# STM32F302x register map
File version: 1.1
Registers are 32-bit, read-write, reset 0x0 unless marked. A register's access mark holds for its fields unless they carry their own. Offsets are from the block's base; [hi:lo] are bit positions; {n}, {i} and the like mark numbered series.

## DBGMCU — Debug support
Base 0xE0042000
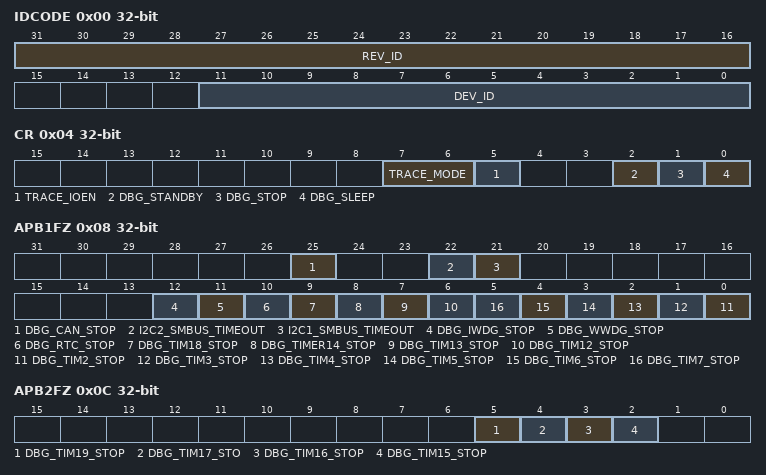
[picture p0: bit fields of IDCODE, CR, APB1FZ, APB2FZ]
0x00 IDCODE ro — MCU Device ID Code Register
  [31:16] REV_ID — Revision Identifier
  [11:0] DEV_ID — Device Identifier
0x04 CR — Debug MCU Configuration Register
  [7:6] TRACE_MODE — Trace pin assignment control
  [5] TRACE_IOEN — Trace pin assignment control
  [2] DBG_STANDBY — Debug Standby Mode
  [1] DBG_STOP — Debug Stop Mode
  [0] DBG_SLEEP — Debug Sleep mode
0x08 APB1FZ — APB Low Freeze Register
  [25] DBG_CAN_STOP — Debug CAN stopped when core is halted
  [22] I2C2_SMBUS_TIMEOUT — SMBUS timeout mode stopped when Core is halted
  [21] I2C1_SMBUS_TIMEOUT — SMBUS timeout mode stopped when Core is halted
  [12] DBG_IWDG_STOP — Debug Independent Wachdog stopped when Core is halted
  [11] DBG_WWDG_STOP — Debug Window Wachdog stopped when Core is halted
  [10] DBG_RTC_STOP — Debug RTC stopped when Core is halted
  [9] DBG_TIM18_STOP — Debug Timer 18 stopped when Core is halted
  [8] DBG_TIMER14_STOP — Debug Timer 14 stopped when Core is halted
  [7] DBG_TIM13_STOP — Debug Timer 13 stopped when Core is halted
  [6] DBG_TIM12_STOP — Debug Timer 12 stopped when Core is halted
  [n-2] DBG_TIM{n}_STOP (n=2..7) — Debug Timer {n} stopped when Core is halted
0x0C APB2FZ — APB High Freeze Register
  [5] DBG_TIM19_STOP — Debug Timer 19 stopped when Core is halted
  [4] DBG_TIM17_STO — Debug Timer 17 stopped when Core is halted
  [3] DBG_TIM16_STOP — Debug Timer 16 stopped when Core is halted
  [2] DBG_TIM15_STOP — Debug Timer 15 stopped when Core is halted

## ADC1 — Analog-to-Digital Converter
Base 0x50000000
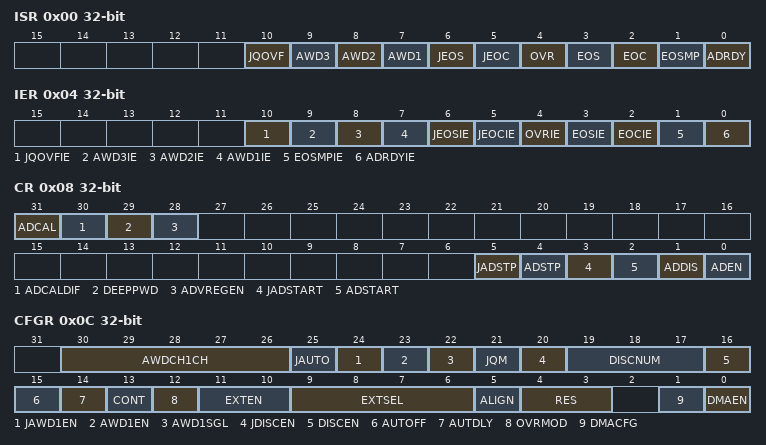
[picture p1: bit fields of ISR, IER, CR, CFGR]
0x00 ISR — interrupt and status register
  [10] JQOVF, [9] AWD3, [8] AWD2, [7] AWD1, [6] JEOS, [5] JEOC, [4] OVR, [3] EOS, [2] EOC, [1] EOSMP, [0] ADRDY
0x04 IER — interrupt enable register
  [10] JQOVFIE, [9] AWD3IE, [8] AWD2IE, [7] AWD1IE, [6] JEOSIE, [5] JEOCIE, [4] OVRIE, [3] EOSIE, [2] EOCIE, [1] EOSMPIE, [0] ADRDYIE
0x08 CR — control register
  [31] ADCAL, [30] ADCALDIF, [29] DEEPPWD, [28] ADVREGEN, [5] JADSTP, [4] ADSTP, [3] JADSTART, [2] ADSTART, [1] ADDIS, [0] ADEN
0x0C CFGR — configuration register
  [30:26] AWDCH1CH, [25] JAUTO, [24] JAWD1EN, [23] AWD1EN, [22] AWD1SGL, [21] JQM, [20] JDISCEN, [19:17] DISCNUM, [16] DISCEN, [15] AUTOFF, [14] AUTDLY, [13] CONT, [12] OVRMOD, [11:10] EXTEN, [9:6] EXTSEL, [5] ALIGN, [4:3] RES, [1] DMACFG, [0] DMAEN
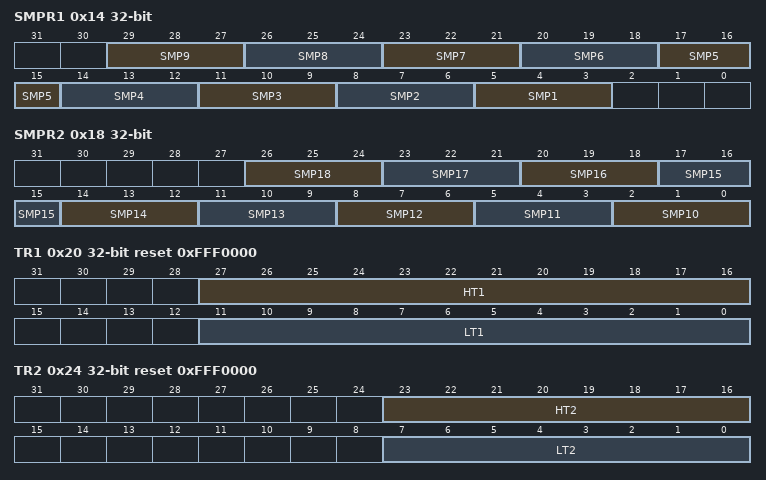
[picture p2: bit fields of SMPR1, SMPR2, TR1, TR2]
0x14 SMPR1 — sample time register 1
  [3n+2:3n] SMP{n} (n=1..9)
0x18 SMPR2 — sample time register 2
  [3n-28:3n-30] SMP{n} (n=10..18)
0x20 TR1 reset 0xFFF0000 — watchdog threshold register 1
  [27:16] HT1, [11:0] LT1
0x24 TR2 reset 0xFFF0000 — watchdog threshold register
  [23:16] HT2, [7:0] LT2
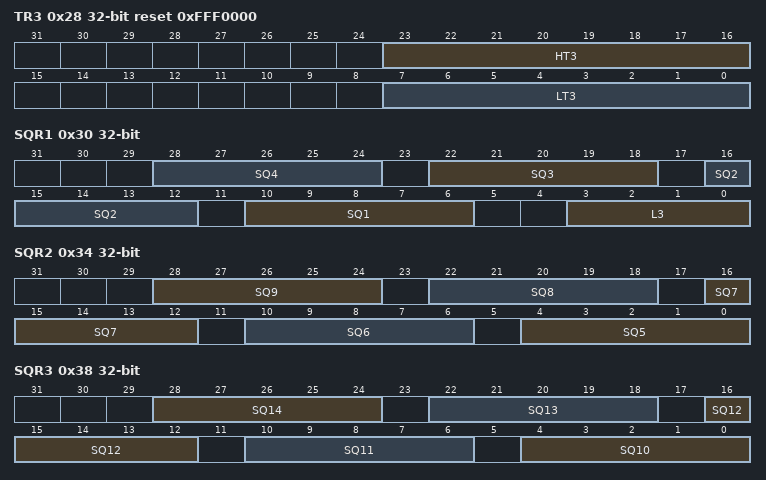
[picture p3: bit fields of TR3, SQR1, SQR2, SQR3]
0x28 TR3 reset 0xFFF0000 — watchdog threshold register 3
  [23:16] HT3, [7:0] LT3
0x30 SQR1 — regular sequence register 1
  [6n+4:6n] SQ{n} (n=1..4), [3:0] L3
0x34 SQR2 — regular sequence register 2
  [6n-26:6n-30] SQ{n} (n=5..9)
0x38 SQR3 — regular sequence register 3
  [6n-56:6n-60] SQ{n} (n=10..14)
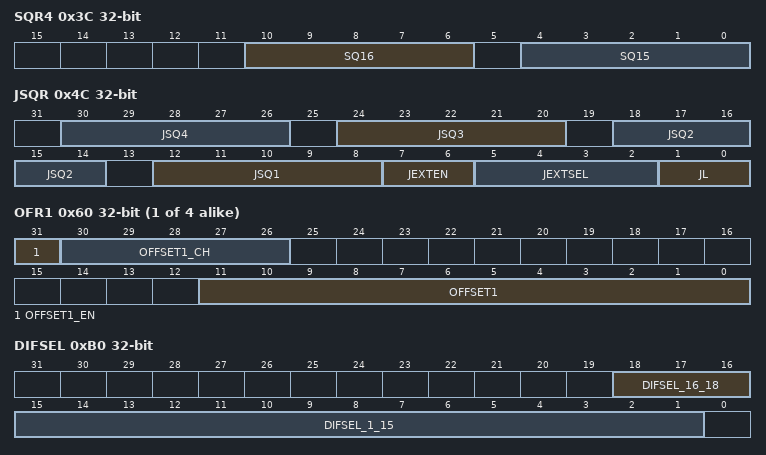
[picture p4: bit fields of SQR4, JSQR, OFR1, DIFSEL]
0x3C SQR4 — regular sequence register 4
  [10:6] SQ16, [4:0] SQ15
0x40 DR ro — regular Data Register
  [15:0] regularDATA
0x4C JSQR — injected sequence register
  [6n+6:6n+2] JSQ{n} (n=1..4), [7:6] JEXTEN, [5:2] JEXTSEL, [1:0] JL
{0x5C+4i} OFR{i} (i=1..4) — offset register {i}
  [31] OFFSET{i}_EN, [30:26] OFFSET{i}_CH, [11:0] OFFSET{i}
{0x7C+4i} JDR{i} ro (i=1..4) — injected data register {i}
  [15:0] JDATA{i}
0xA0 AWD2CR — Analog Watchdog 2 Configuration Register
  [18:1] AWD2CH
0xA4 AWD3CR — Analog Watchdog 3 Configuration Register
  [18:1] AWD3CH
0xB0 DIFSEL access per field — Differential Mode Selection Register 2
  [18:16] DIFSEL_16_18 ro — Differential mode for channels 18 to 16
  [15:1] DIFSEL_1_15 rw — Differential mode for channels 15 to 1
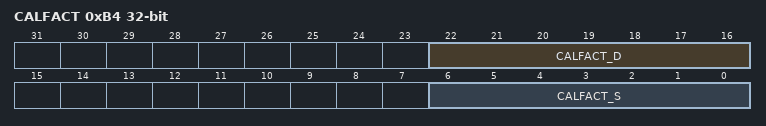
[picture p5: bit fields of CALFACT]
0xB4 CALFACT — Calibration Factors
  [22:16] CALFACT_D, [6:0] CALFACT_S

## SYSCFG — System configuration controller
Base 0x40010000
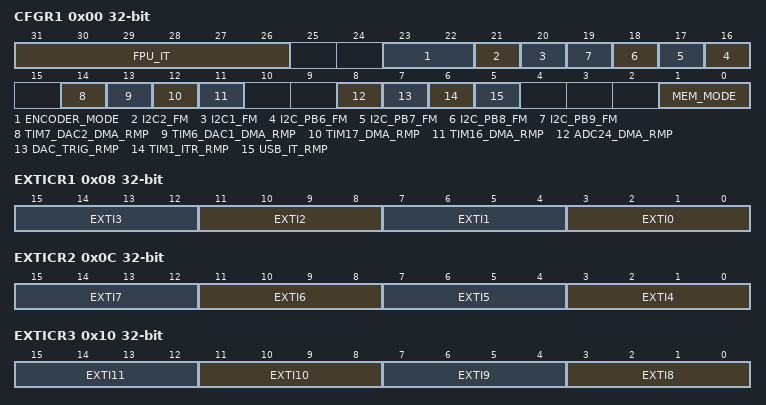
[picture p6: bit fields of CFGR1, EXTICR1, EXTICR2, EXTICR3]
0x00 CFGR1 — configuration register 1
  [31:26] FPU_IT — Interrupt enable bits from FPU
  [23:22] ENCODER_MODE
  [21] I2C2_FM — I2C2 Fast Mode Plus
  [20] I2C1_FM — I2C1 Fast Mode Plus
  [n+10] I2C_PB{n}_FM (n=6..9) — Fast Mode Plus (FM+) driving capability activation bits.
  [14] TIM7_DAC2_DMA_RMP — TIM7 and DAC2 DMA request remapping bit
  [13] TIM6_DAC1_DMA_RMP — TIM6 and DAC1 DMA request remapping bit
  [12] TIM17_DMA_RMP — TIM17 DMA request remapping bit
  [11] TIM16_DMA_RMP — TIM16 DMA request remapping bit
  [8] ADC24_DMA_RMP — ADC24 DMA remapping bit
  [7] DAC_TRIG_RMP — DAC trigger remap (when TSEL = 001)
  [6] TIM1_ITR_RMP — Timer 1 ITR3 selection
  [5] USB_IT_RMP — USB interrupt remap
  [1:0] MEM_MODE — Memory mapping selection bits
0x08 EXTICR1 — external interrupt configuration register 1
  [4n+3:4n] EXTI{n} (n=0..3) — EXTI {n} configuration bits
0x0C EXTICR2 — external interrupt configuration register 2
  [4n-13:4n-16] EXTI{n} (n=4..7) — EXTI {n} configuration bits
0x10 EXTICR3 — external interrupt configuration register 3
  [4n-29:4n-32] EXTI{n} (n=8..11) — EXTI {n} configuration bits
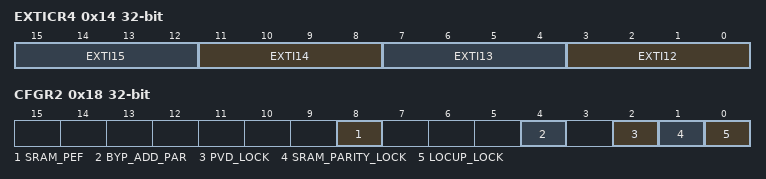
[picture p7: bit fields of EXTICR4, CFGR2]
0x14 EXTICR4 — external interrupt configuration register 4
  [4n-45:4n-48] EXTI{n} (n=12..15) — EXTI {n} configuration bits
0x18 CFGR2 — configuration register 2
  [8] SRAM_PEF — SRAM parity flag
  [4] BYP_ADD_PAR — Bypass address bit 29 in parity calculation
  [2] PVD_LOCK — PVD lock enable bit
  [1] SRAM_PARITY_LOCK — SRAM parity lock bit
  [0] LOCUP_LOCK — Cortex-M0 LOCKUP bit enable bit

## OPAMP — Operational amplifier
Base 0x40010038
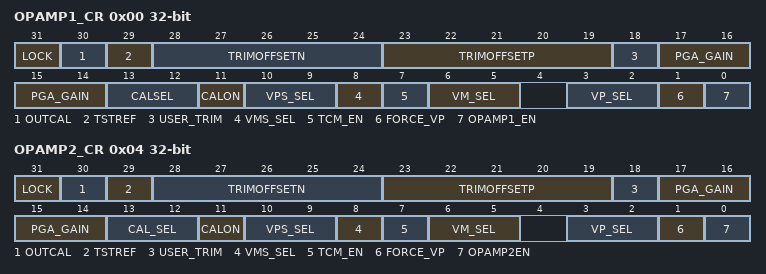
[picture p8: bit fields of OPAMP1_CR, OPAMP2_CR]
0x00 OPAMP1_CR access per field — OPAMP1 control register
  [31] LOCK rw — OPAMP 1 lock
  [30] OUTCAL ro — OPAMP 1 ouput status flag
  [29] TSTREF rw
  [28:24] TRIMOFFSETN rw — Offset trimming value (NMOS)
  [23:19] TRIMOFFSETP rw — Offset trimming value (PMOS)
  [18] USER_TRIM rw — User trimming enable
  [17:14] PGA_GAIN rw — Gain in PGA mode
  [13:12] CALSEL rw — Calibration selection
  [11] CALON rw — Calibration mode enable
  [10:9] VPS_SEL rw — OPAMP1 Non inverting input secondary selection
  [8] VMS_SEL rw — OPAMP1 inverting input secondary selection
  [7] TCM_EN rw — Timer controlled Mux mode enable
  [6:5] VM_SEL rw — OPAMP1 inverting input selection
  [3:2] VP_SEL rw — OPAMP1 Non inverting input selection
  [1] FORCE_VP rw
  [0] OPAMP1_EN rw — OPAMP1 enable
0x04 OPAMP2_CR access per field — OPAMP2 control register
  [31] LOCK rw — OPAMP 2 lock
  [30] OUTCAL ro — OPAMP 2 ouput status flag
  [29] TSTREF rw
  [28:24] TRIMOFFSETN rw — Offset trimming value (NMOS)
  [23:19] TRIMOFFSETP rw — Offset trimming value (PMOS)
  [18] USER_TRIM rw — User trimming enable
  [17:14] PGA_GAIN rw — Gain in PGA mode
  [13:12] CAL_SEL rw — Calibration selection
  [11] CALON rw — Calibration mode enable
  [10:9] VPS_SEL rw — OPAMP2 Non inverting input secondary selection
  [8] VMS_SEL rw — OPAMP2 inverting input secondary selection
  [7] TCM_EN rw — Timer controlled Mux mode enable
  [6:5] VM_SEL rw — OPAMP2 inverting input selection
  [3:2] VP_SEL rw — OPAMP2 Non inverting input selection
  [1] FORCE_VP rw
  [0] OPAMP2EN rw — OPAMP2 enable
